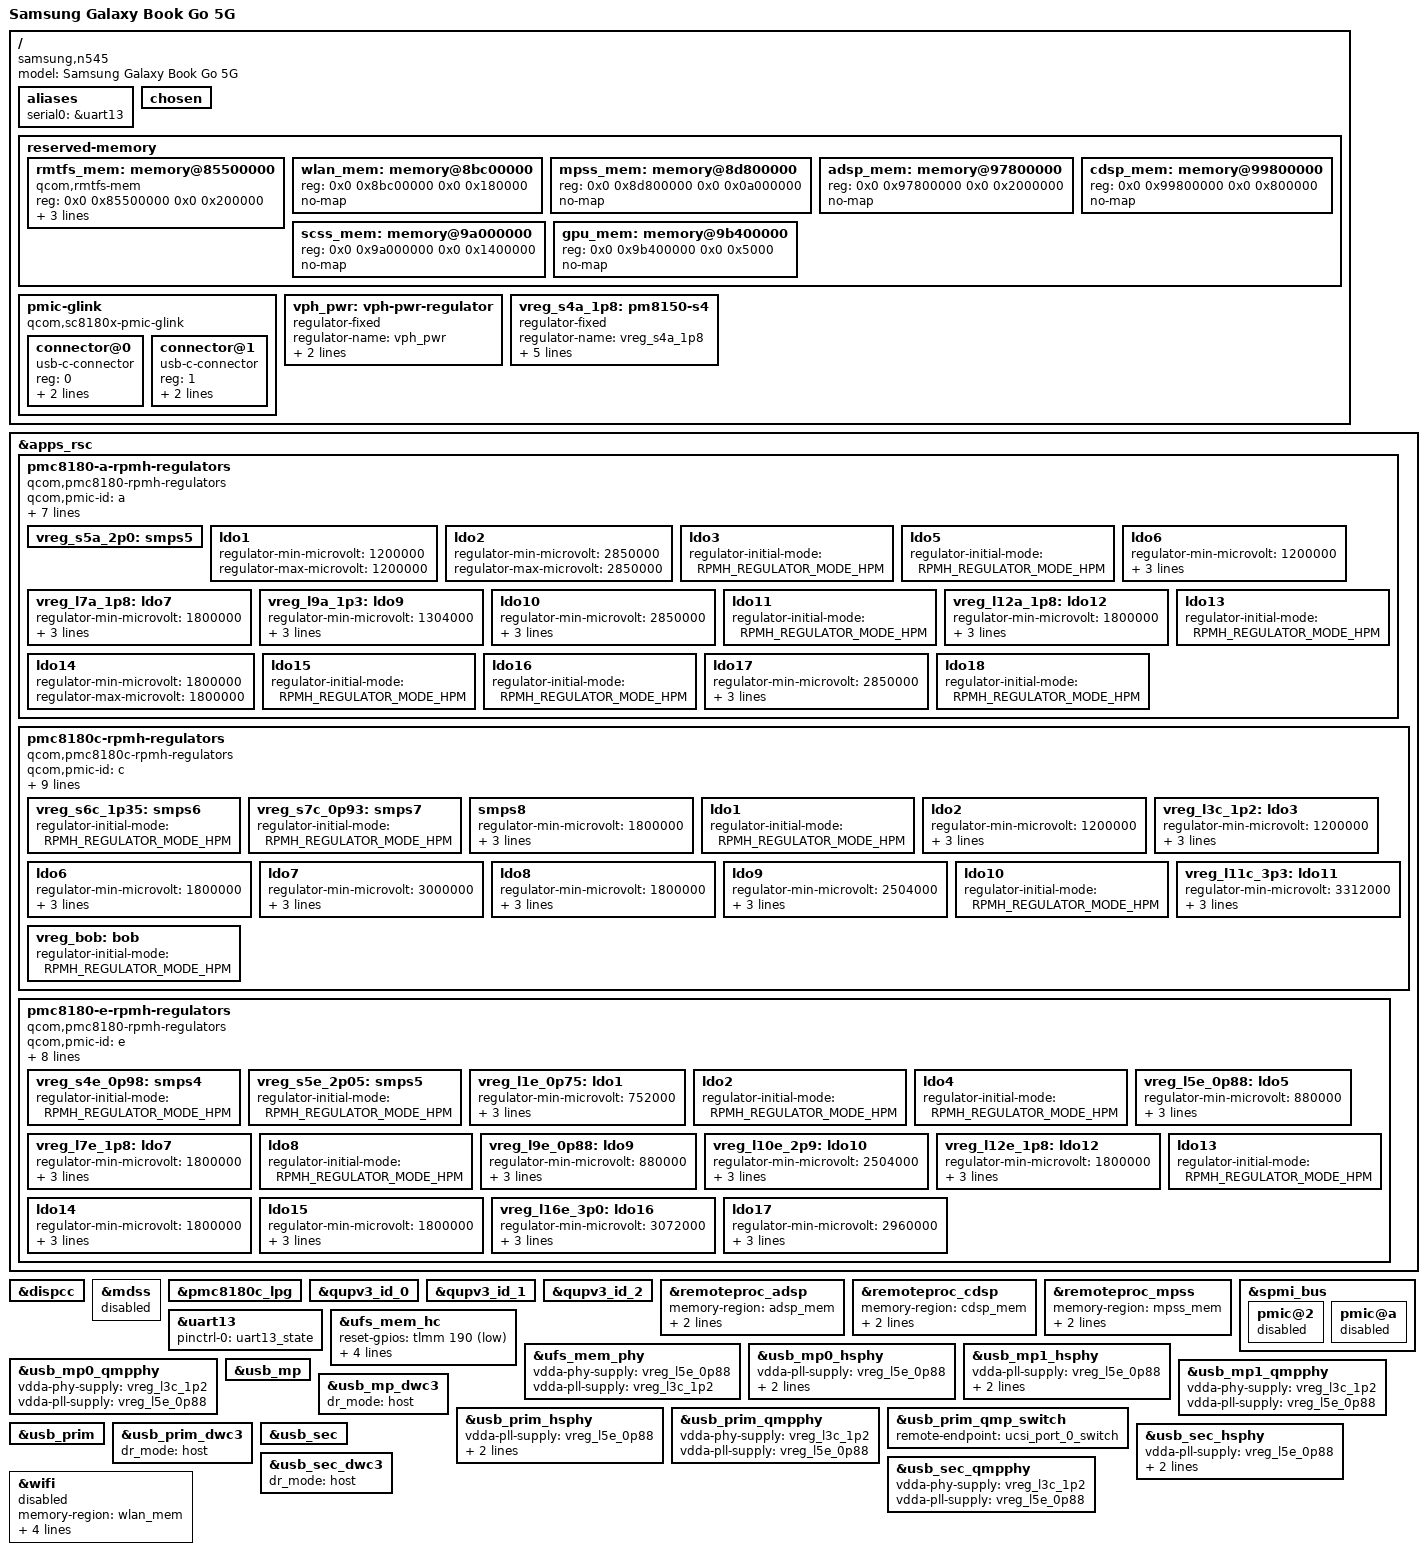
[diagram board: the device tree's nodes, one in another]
// SPDX-License-Identifier: BSD-3-Clause
/*
 * Copyright (c) 2022, The Linux Foundation. All rights reserved.
 */

/dts-v1/;

#include <dt-bindings/regulator/qcom,rpmh-regulator.h>
#include <dt-bindings/gpio/gpio.h>
#include "sc8180x.dtsi"
#include "sc8180x-pmics.dtsi"

/ {
	model = "Samsung Galaxy Book Go 5G";
	compatible = "samsung,n545", "qcom,sc8180x";

	aliases {
		serial0 = &uart13;
	};

	chosen { };

	reserved-memory {

        // Sources for memory regions:
		// - Windows Device Manager/ACPI
		// - Windows Registry/driver .inf files

		// Windows Registry entries:
		//
		// - ADSP:
		//   - ADSP:
        //   - alignment:    0x00100000
        //   - reservation:  0x02200000
        //
        // - CDSP:
        //   - alignment:    0x00100000
        //   - reservation:  0x00800000
        //
        // - GFXSUC:
        //   - alignment:    0x00001000
        //   - reservation:  0x00005000
        //
        // - MPSS/MODEM:
        //   - address:      0x8d800000
        //   - alignment:    0x00400000
        //   - reservation:  0x03000000
        //
        // - SCSS/SLPI:
        //   - alignment:    0x00100000
        //   - reservation:  0x01400000
        //
        // - IPA (no firmware?):
        //   - alignment:    0x00100000
        //   - reservation:  0x00100000
        //
        // - SPSS (no firmware?):
        //   - alignment:    0x00100000
        //   - reservation:  0x00100000
        //
        // - MBA (bogus?):
        //   - alignment:    0x00100000
        //
        // - VENUS (bogus?):
        //   - alignment:          0x0
        //   - reservation:  0x00500000
        //
        // - WCNSS (bogus?):
        //   - alignment:    0x00100000
        //   - reservation:        0x0

		// Windows Device Manager memory map:
		//
		// [...]
		// 0x85d00000 ++  0x200000	RMTFS
		// 0x85f00000 ++ 0x5d00000	<free>
		// 0x8b700000 ++  0x500000	CAMERA
		// 0x8bc00000 ++  0x180000	WLAN
		// 0x8bd80000 ++ 0xe780000	<free for image loader>
		// 0x9a500000 ++  0x600000	QSM
		// [...]

		// Resulting memory map:
		//
		// [...]
		// 0x85500000 ++  0x200000	RMTFS
		// 0x85700000
		// 0x85f00000 ++ 0x5d00000	<reserved>
		// 0x8b700000 ++  0x500000	CAMERA
		// 0x8bc00000 ++  0x180000	WLAN
		// 0x8bd80000 ++ 0x1a80000	<free>
		// 0x8d800000 ++ 0x9600000	MPSS
		// 0x96e00000 ++ 0x1a00000	ADSP
		// 0x98800000 ++  0x800000	CDSP
		// 0x99000000 ++ 0x1400000	SCSS
		// 0x9a400000 ++    0x5000	GFXSUC
		// 0x9a405000 ++   0xfb000	<free>
		// 0x9a500000 ++  0x600000	QSM
		// [...]
		/* Note: rmtfs region in ACPI/Windows starts from 0x85d00000 */
        
		rmtfs_mem: memory@85500000 {
			compatible = "qcom,rmtfs-mem";
			reg = <0x0 0x85500000 0x0 0x200000>;
			no-map;

			qcom,client-id = <1>;
			qcom,vmid = <15>;
		};

		wlan_mem: memory@8bc00000 {
			reg = <0x0 0x8bc00000 0x0 0x180000>;
			no-map;
		};

		mpss_mem: memory@8d800000 {
			reg = <0x0 0x8d800000 0x0 0x0a000000>;
			no-map;
		};

		adsp_mem: memory@97800000 {
			reg = <0x0 0x97800000 0x0 0x2000000>;
			no-map;
		};

		cdsp_mem: memory@99800000 {
			reg = <0x0 0x99800000 0x0 0x800000>;
			no-map;
		};

		scss_mem: memory@9a000000 {
			reg = <0x0 0x9a000000 0x0 0x1400000>;
			no-map;
		};

		gpu_mem: memory@9b400000 {
			reg = <0x0 0x9b400000 0x0 0x5000>;
			no-map;
		};
	};

	pmic-glink {
		compatible = "qcom,sc8180x-pmic-glink", "qcom,pmic-glink";

		#address-cells = <1>;
		#size-cells = <0>;

		connector@0 {
			compatible = "usb-c-connector";
			reg = <0>;
			power-role = "dual";
			data-role = "dual";
		};

		connector@1 {
			compatible = "usb-c-connector";
			reg = <1>;
			power-role = "dual";
			data-role = "dual";
		};
	};

	vph_pwr: vph-pwr-regulator {
		compatible = "regulator-fixed";
		regulator-name = "vph_pwr";
		regulator-min-microvolt = <3700000>;
		regulator-max-microvolt = <3700000>;
	};

	vreg_s4a_1p8: pm8150-s4 {
		compatible = "regulator-fixed";
		regulator-name = "vreg_s4a_1p8";

		regulator-min-microvolt = <1800000>;
		regulator-max-microvolt = <1800000>;

		regulator-always-on;
		regulator-boot-on;

		vin-supply = <&vph_pwr>;
	};
};

&apps_rsc {
	pmc8180-a-rpmh-regulators {
		compatible = "qcom,pmc8180-rpmh-regulators";
		qcom,pmic-id = "a";

		vdd-s5-supply = <&vph_pwr>;
		vdd-l1-l8-l11-supply = <&vreg_s6c_1p35>;
		vdd-l2-l10-supply = <&vreg_bob>;
		vdd-l3-l4-l5-l18 = <&vreg_s7c_0p93>;
		vdd-l6-l9-supply = <&vreg_s6c_1p35>;
		vdd-l7-l12-l14-l15-supply = <&vreg_s5a_2p0>;
		vdd-l13-l16-l17-supply = <&vreg_bob>;

		vreg_s5a_2p0: smps5 {
			/* voltage constraints are not in ACPI */
		};

		ldo1 {
			regulator-min-microvolt = <1200000>;
			regulator-max-microvolt = <1200000>;
			// regulator-initial-mode = <RPMH_REGULATOR_MODE_HPM>;
		};

		ldo2 {
			regulator-min-microvolt = <2850000>;
			regulator-max-microvolt = <2850000>;
			/* failed to set initial mode -ETIMEDOUT */ 
			// regulator-initial-mode = <RPMH_REGULATOR_MODE_HPM>;
		};

		ldo3 {
			/* voltage constraints are not in ACPI */
			regulator-initial-mode = <RPMH_REGULATOR_MODE_HPM>;
		};

		ldo5 {
			/* voltage constraints are not in ACPI */
			regulator-initial-mode = <RPMH_REGULATOR_MODE_HPM>;
		};

		ldo6 {
			regulator-min-microvolt = <1200000>;
			regulator-max-microvolt = <1200000>;
			regulator-initial-mode = <RPMH_REGULATOR_MODE_HPM>;
		};

		vreg_l7a_1p8: ldo7 {
			regulator-min-microvolt = <1800000>;
			regulator-max-microvolt = <1800000>;
			regulator-initial-mode = <RPMH_REGULATOR_MODE_HPM>;
		};

		vreg_l9a_1p3: ldo9 {
			regulator-min-microvolt = <1304000>;
			regulator-max-microvolt = <1304000>;
			regulator-initial-mode = <RPMH_REGULATOR_MODE_HPM>;
		};

		ldo10 {
			regulator-min-microvolt = <2850000>;
			regulator-max-microvolt = <3000000>;
			regulator-initial-mode = <RPMH_REGULATOR_MODE_HPM>;
		};

		ldo11 {
			/* voltage constraints are not in ACPI */
			regulator-initial-mode = <RPMH_REGULATOR_MODE_HPM>;
		};

		vreg_l12a_1p8: ldo12 {
			regulator-min-microvolt = <1800000>;
			regulator-max-microvolt = <1800000>;
			regulator-initial-mode = <RPMH_REGULATOR_MODE_HPM>;
		};

		ldo13 {
			/* voltage constraints are not in ACPI */
			regulator-initial-mode = <RPMH_REGULATOR_MODE_HPM>;
		};

		ldo14 {
			regulator-min-microvolt = <1800000>;
			regulator-max-microvolt = <1800000>;
			/* failed to set initial mode -ETIMEDOUT */ 
			//regulator-initial-mode = <RPMH_REGULATOR_MODE_HPM>;
		}; 

		ldo15 {
			/* voltage constraints are not in ACPI */
			regulator-initial-mode = <RPMH_REGULATOR_MODE_HPM>;
		};

		ldo16 {
			/* voltage constraints are not in ACPI */
			regulator-initial-mode = <RPMH_REGULATOR_MODE_HPM>;
		};

		/* ldo17 causes failed to get current voltage -ENOTRECOVERABLE */

		ldo17 {
			regulator-min-microvolt = <2850000>;
			regulator-max-microvolt = <2850000>;
			regulator-initial-mode = <RPMH_REGULATOR_MODE_HPM>;
		};

		ldo18 {
			/* voltage constraints are not in ACPI */
			regulator-initial-mode = <RPMH_REGULATOR_MODE_HPM>;
		};
	};

	pmc8180c-rpmh-regulators {
		compatible = "qcom,pmc8180c-rpmh-regulators";
		qcom,pmic-id = "c";

		vdd-s6-supply = <&vph_pwr>;
		vdd-s7-supply = <&vph_pwr>;
		vdd-s8-supply = <&vph_pwr>; // ?
		vdd-l1-l8-supply = <&vreg_s4a_1p8>;
		vdd-l2-l3-supply = <&vreg_s6c_1p35>;
		vdd-l4-l5-l6-supply = <&vreg_bob>;
		vdd-l7-l11-supply = <&vreg_bob>;
		vdd-l9-l10 = <&vreg_bob>;
		vdd-bob-supply = <&vph_pwr>;

		vreg_s6c_1p35: smps6 {
			/* voltage constraints are not in ACPI */
			regulator-initial-mode = <RPMH_REGULATOR_MODE_HPM>;
		};

		vreg_s7c_0p93: smps7 {
			/* voltage constraints are not in ACPI */
			regulator-initial-mode = <RPMH_REGULATOR_MODE_HPM>;
		};

		smps8 {
			regulator-min-microvolt = <1800000>;
			regulator-max-microvolt = <1800000>;
			regulator-initial-mode = <RPMH_REGULATOR_MODE_HPM>;
		};

		ldo1 {
			/* voltage constraints are not in ACPI */
			regulator-initial-mode = <RPMH_REGULATOR_MODE_HPM>;
		};

		ldo2 {
			regulator-min-microvolt = <1200000>;
			regulator-max-microvolt = <1200000>;
			regulator-initial-mode = <RPMH_REGULATOR_MODE_HPM>;
		};

		vreg_l3c_1p2: ldo3 {
			regulator-min-microvolt = <1200000>;
			regulator-max-microvolt = <1200000>;
			regulator-initial-mode = <RPMH_REGULATOR_MODE_HPM>;
		};

		/* ldo4 is needed for touch, but causes failed to get current voltage -ENOTRECOVERABLE */

		// vreg_l4c_3v3: ldo4 {
		// 	regulator-min-microvolt = <3300000>;
		// 	regulator-max-microvolt = <3300000>;
		// 	regulator-initial-mode = <RPMH_REGULATOR_MODE_HPM>;
		// };

		ldo6 { /* sd card vqmmc? */
			regulator-min-microvolt = <1800000>;
			regulator-max-microvolt = <2950000>;
			regulator-initial-mode = <RPMH_REGULATOR_MODE_HPM>;
		};

		ldo7 {
			regulator-min-microvolt = <3000000>;
			regulator-max-microvolt = <3000000>;
			regulator-initial-mode = <RPMH_REGULATOR_MODE_HPM>;
		};

		ldo8 {
			regulator-min-microvolt = <1800000>;
			regulator-max-microvolt = <1800000>;
			regulator-initial-mode = <RPMH_REGULATOR_MODE_HPM>;
		};

		ldo9 {
			regulator-min-microvolt = <2504000>;
			regulator-max-microvolt = <2904000>;
			regulator-initial-mode = <RPMH_REGULATOR_MODE_HPM>;
		};

		ldo10 {
			/* voltage constraints are not in ACPI */
			regulator-initial-mode = <RPMH_REGULATOR_MODE_HPM>;
		};

		vreg_l11c_3p3: ldo11 {
			regulator-min-microvolt = <3312000>; // 3000000
			regulator-max-microvolt = <3312000>;
			regulator-initial-mode = <RPMH_REGULATOR_MODE_HPM>;
		};

		vreg_bob: bob {
			/* voltage constraints are not in ACPI */
			regulator-initial-mode = <RPMH_REGULATOR_MODE_HPM>;
		};
	};

	pmc8180-e-rpmh-regulators {
		compatible = "qcom,pmc8180-rpmh-regulators";
		qcom,pmic-id = "e";

		vdd-s4-supply = <&vph_pwr>;
		vdd-s5-supply = <&vph_pwr>;
		vdd-l1-l8-l11-supply = <&vreg_s4e_0p98>;
		vdd-l2-l10-supply = <&vreg_bob>;
		vdd-l3-l4-l5-l18-supply = <&vreg_s4e_0p98>;
		vdd-l6-l9-supply = <&vreg_s4e_0p98>;
		vdd-l7-l12-l14-l15-supply = <&vreg_s5e_2p05>;
		vdd-l13-l16-l17-supply = <&vreg_bob>;

		vreg_s4e_0p98: smps4 {
			/* voltage constraints are not in ACIP */
			regulator-initial-mode = <RPMH_REGULATOR_MODE_HPM>;
		};

		vreg_s5e_2p05: smps5 {
			/* voltage constraints are not in ACPI */
			regulator-initial-mode = <RPMH_REGULATOR_MODE_HPM>;
		};

		vreg_l1e_0p75: ldo1 {
			regulator-min-microvolt = <752000>;
			regulator-max-microvolt = <752000>;
			regulator-initial-mode = <RPMH_REGULATOR_MODE_HPM>;
		};

		ldo2 {
			/* voltage constraints are not in ACPI */
			regulator-initial-mode = <RPMH_REGULATOR_MODE_HPM>;
		};

		ldo4 {
			/* voltage constraints are not in ACPI */
			regulator-initial-mode = <RPMH_REGULATOR_MODE_HPM>;
		};

		vreg_l5e_0p88: ldo5 {
			regulator-min-microvolt = <880000>;
			regulator-max-microvolt = <880000>;
			regulator-initial-mode = <RPMH_REGULATOR_MODE_HPM>;
		};

		vreg_l7e_1p8: ldo7 {
			regulator-min-microvolt = <1800000>;
			regulator-max-microvolt = <1800000>;
			regulator-initial-mode = <RPMH_REGULATOR_MODE_HPM>;
		};

		ldo8 {
			/* voltage constraints are not in ACPI */
			regulator-initial-mode = <RPMH_REGULATOR_MODE_HPM>;
		};

		vreg_l9e_0p88: ldo9 {
			regulator-min-microvolt = <880000>;
			regulator-max-microvolt = <912000>;
			regulator-initial-mode = <RPMH_REGULATOR_MODE_HPM>;
		};

		vreg_l10e_2p9: ldo10 {
			regulator-min-microvolt = <2504000>; // 2904000?
			regulator-max-microvolt = <2904000>;
			regulator-initial-mode = <RPMH_REGULATOR_MODE_HPM>;
		};

		vreg_l12e_1p8: ldo12 {
			regulator-min-microvolt = <1800000>;
			regulator-max-microvolt = <1800000>;
			regulator-initial-mode = <RPMH_REGULATOR_MODE_HPM>;
		};

		ldo13 {
			/* voltage constraints are not in ACPI */
			regulator-initial-mode = <RPMH_REGULATOR_MODE_HPM>;
		};

		ldo14 {
			regulator-min-microvolt = <1800000>;
			regulator-max-microvolt = <1800000>;
			regulator-initial-mode = <RPMH_REGULATOR_MODE_HPM>;
		};

		ldo15 {
			regulator-min-microvolt = <1800000>;
			regulator-max-microvolt = <1800000>;
			regulator-initial-mode = <RPMH_REGULATOR_MODE_HPM>;
		};

		vreg_l16e_3p0: ldo16 {
			regulator-min-microvolt = <3072000>;
			regulator-max-microvolt = <3072000>;
			regulator-initial-mode = <RPMH_REGULATOR_MODE_HPM>;
		};

		ldo17 {
			regulator-min-microvolt = <2960000>;
			regulator-max-microvolt = <2960000>;
			regulator-initial-mode = <RPMH_REGULATOR_MODE_HPM>;
		};
	};
};

&dispcc {
	status = "okay";
};


&mdss {
	status = "disabled";
};

&pmc8180c_lpg {
	status = "okay";
};

&qupv3_id_0 {
	status = "okay";
};

&qupv3_id_1 {
	status = "okay";
};

&qupv3_id_2 {
	status = "okay";
};

&remoteproc_adsp {
	status = "okay";
	memory-region = <&adsp_mem>;
	firmware-name = "qcom/samsung/n545/qcadsp8180.mbn";
};

&remoteproc_cdsp {
	status = "okay";

	memory-region = <&cdsp_mem>;
	firmware-name = "qcom/samsung/n545/qccdsp8180.mbn";
};

&remoteproc_mpss {
	status = "okay";

	memory-region = <&mpss_mem>;
	firmware-name = "qcom/samsung/n545/qcmpss8180_XEF.mbn";
};

&spmi_bus {
	pmic@2 {
		status = "disabled";
	};
	pmic@a {
		status = "disabled";
	};
};

&uart13 {
	status = "okay";

	pinctrl-names = "default";
	pinctrl-0 = <&uart13_state>;
};

&ufs_mem_hc {
	status = "okay";

	reset-gpios = <&tlmm 190 GPIO_ACTIVE_LOW>;

	vcc-supply = <&vreg_l10e_2p9>;
	vcc-max-microamp = <155000>;

	vccq2-supply = <&vreg_l7e_1p8>;
	vccq2-max-microamp = <425000>;
};

&ufs_mem_phy {
	status = "okay";

	vdda-phy-supply = <&vreg_l5e_0p88>;
	vdda-pll-supply = <&vreg_l3c_1p2>;
};

&usb_mp0_hsphy {
	status = "okay";
	vdda-pll-supply = <&vreg_l5e_0p88>;
	vdda18-supply = <&vreg_l12a_1p8>;
	vdda33-supply = <&vreg_l16e_3p0>;
};

&usb_mp1_hsphy {
	status = "okay";
	vdda-pll-supply = <&vreg_l5e_0p88>;
	vdda18-supply = <&vreg_l12a_1p8>;
	vdda33-supply = <&vreg_l16e_3p0>;
};

&usb_mp0_qmpphy {
	status = "okay";
	vdda-phy-supply = <&vreg_l3c_1p2>;
	vdda-pll-supply = <&vreg_l5e_0p88>;
};

&usb_mp1_qmpphy {
	status = "okay";
	vdda-phy-supply = <&vreg_l3c_1p2>;
	vdda-pll-supply = <&vreg_l5e_0p88>;
};

&usb_mp {
	status = "okay";
};

&usb_mp_dwc3 {
	dr_mode = "host";
};

&usb_prim_hsphy {
	status = "okay";

	vdda-pll-supply = <&vreg_l5e_0p88>;
	vdda18-supply = <&vreg_l12a_1p8>;
	vdda33-supply = <&vreg_l16e_3p0>;
};

&usb_prim_qmpphy {
	status = "okay";

	vdda-phy-supply = <&vreg_l3c_1p2>;
	vdda-pll-supply = <&vreg_l5e_0p88>;
};

&usb_prim_qmp_switch {
	remote-endpoint = <&ucsi_port_0_switch>;
};

&usb_prim {
	status = "okay";
};

&usb_prim_dwc3 {
	dr_mode = "host";
};

&usb_sec_hsphy {
	status = "okay";

	vdda-pll-supply = <&vreg_l5e_0p88>;
	vdda18-supply = <&vreg_l12a_1p8>;
	vdda33-supply = <&vreg_l16e_3p0>;
};

&usb_sec_qmpphy {
	status = "okay";

	vdda-phy-supply = <&vreg_l3c_1p2>;
	vdda-pll-supply = <&vreg_l5e_0p88>;
};

// &usb_sec_qmp_switch {
// 	remote-endpoint = <&ucsi_port_1_switch>;
// };

&usb_sec {
	status = "okay";
};

&usb_sec_dwc3 {
	dr_mode = "host";
};

&wifi {
	status = "disabled";

	memory-region = <&wlan_mem>;

	vdd-0.8-cx-mx-supply = <&vreg_l1e_0p75>;
	vdd-1.8-xo-supply = <&vreg_l7a_1p8>;
	vdd-1.3-rfa-supply = <&vreg_l9a_1p3>;
	vdd-3.3-ch0-supply = <&vreg_l11c_3p3>;
	//vdd-3.3-ch1-supply = <&vreg_l10c_3p3>; not used?
};
